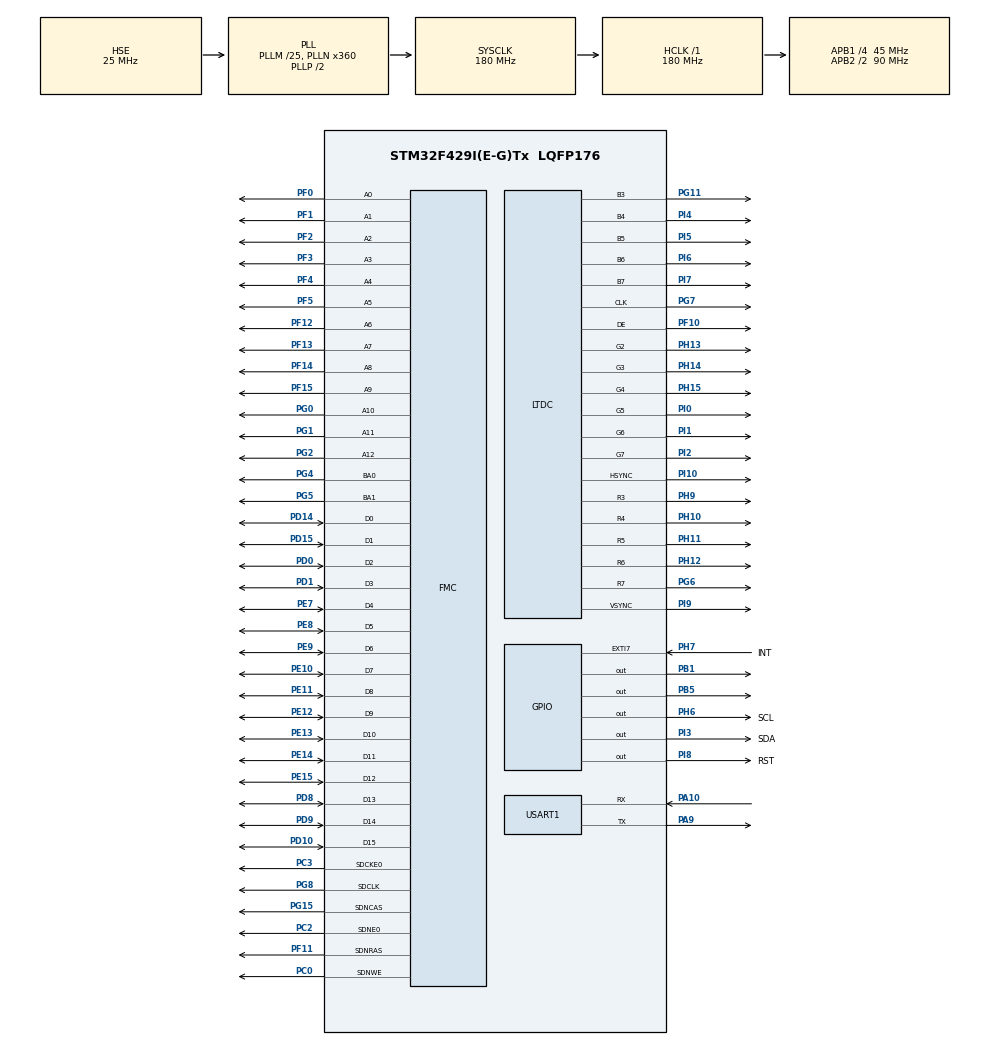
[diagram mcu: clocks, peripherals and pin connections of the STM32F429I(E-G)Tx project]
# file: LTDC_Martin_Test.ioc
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DMA2D.ColorMode=DMA2D_OUTPUT_RGB565
DMA2D.Mode=DMA2D_R2M
FMC.CASLatency1=FMC_SDRAM_CAS_LATENCY_3
FMC.ColumnBitsNumber1=FMC_SDRAM_COLUMN_BITS_NUM_9
FMC.ExitSelfRefreshDelay1=8
FMC.LoadToActiveDelay1=2
FMC.RCDDelay1=2
FMC.RPDelay1=2
FMC.ReadPipeDelay1=FMC_SDRAM_RPIPE_DELAY_1
FMC.RowCycleDelay1=6
FMC.SDClockPeriod1=FMC_SDRAM_CLOCK_PERIOD_2
FMC.SelfRefreshTime1=6
FMC.WriteRecoveryTime1=4
FREERTOS.Tasks01=LEDTask,24,128,StartDefaultTask,Default,NULL,Dynamic,NULL,NULL;LCDTask,8,128,StartTask02,Default,NULL,Dynamic,NULL,NULL
LTDC.ActiveW=800
LTDC.Alpha_L0=255
LTDC.FBStartAdress_L0=0xC0000000
LTDC.FBStartAdress_L1=0xC0200000
LTDC.HBP=88
LTDC.HFP=40
LTDC.HSync=48
LTDC.ImageHeight_L0=600
LTDC.ImageHeight_L1=600
LTDC.ImageWidth_L0=1024
LTDC.ImageWidth_L1=1024
LTDC.PixelFormat_L0=LTDC_PIXEL_FORMAT_RGB565
LTDC.PixelFormat_L1=LTDC_PIXEL_FORMAT_RGB565
LTDC.VBP=32
LTDC.VFP=13
LTDC.VSPolarity=LTDC_VSPOLARITY_AL
LTDC.VSync=3
LTDC.WindowX1_L0=1024
LTDC.WindowX1_L1=1024
LTDC.WindowY1_L0=600
LTDC.WindowY1_L1=600
Mcu.Family=STM32F4
Mcu.Name=STM32F429I(E-G)Tx
Mcu.Package=LQFP176
NVIC.DMA2D_IRQn=true\:5\:0\:false\:false\:true\:true\:true\:true\:true
NVIC.EXTI9_5_IRQn=true\:1\:1\:true\:false\:true\:true\:true\:true\:true
NVIC.PriorityGroup=NVIC_PRIORITYGROUP_4
NVIC.USART1_IRQn=true\:1\:1\:true\:false\:true\:true\:true\:true\:true
PA10.Mode=Asynchronous
PA10.Signal=USART1_RX
PA9.Mode=Asynchronous
PA9.Signal=USART1_TX
PB1.Signal=GPIO_Output
PB5.GPIO_PuPd=GPIO_PULLUP
PB5.GPIO_Speed=GPIO_SPEED_FREQ_VERY_HIGH
PB5.PinState=GPIO_PIN_SET
PB5.Signal=GPIO_Output
PC0.GPIO_PuPd=GPIO_PULLUP
PC0.Signal=FMC_SDNWE
PC2.GPIO_PuPd=GPIO_PULLUP
PC2.Mode=SdramChipSelect1_1
PC2.Signal=FMC_SDNE0
PC3.GPIO_PuPd=GPIO_PULLUP
PC3.Mode=SdramChipSelect1_1
PC3.Signal=FMC_SDCKE0
PD0.GPIO_PuPd=GPIO_PULLUP
PD0.Signal=FMC_D2_DA2
PD1.GPIO_PuPd=GPIO_PULLUP
PD1.Signal=FMC_D3_DA3
PD10.GPIO_PuPd=GPIO_PULLUP
PD10.Signal=FMC_D15_DA15
PD14.GPIO_PuPd=GPIO_PULLUP
PD14.Signal=FMC_D0_DA0
PD15.GPIO_PuPd=GPIO_PULLUP
PD15.Signal=FMC_D1_DA1
PD8.GPIO_PuPd=GPIO_PULLUP
PD8.Signal=FMC_D13_DA13
PD9.GPIO_PuPd=GPIO_PULLUP
PD9.Signal=FMC_D14_DA14
PE0.Signal=FMC_NBL0
PE1.Signal=FMC_NBL1
PE10.GPIO_PuPd=GPIO_PULLUP
PE10.Signal=FMC_D7_DA7
PE11.GPIO_PuPd=GPIO_PULLUP
PE11.Signal=FMC_D8_DA8
PE12.GPIO_PuPd=GPIO_PULLUP
PE12.Signal=FMC_D9_DA9
PE13.GPIO_PuPd=GPIO_PULLUP
PE13.Signal=FMC_D10_DA10
PE14.GPIO_PuPd=GPIO_PULLUP
PE14.Signal=FMC_D11_DA11
PE15.GPIO_PuPd=GPIO_PULLUP
PE15.Signal=FMC_D12_DA12
PE7.GPIO_PuPd=GPIO_PULLUP
PE7.Signal=FMC_D4_DA4
PE8.GPIO_PuPd=GPIO_PULLUP
PE8.Signal=FMC_D5_DA5
PE9.GPIO_PuPd=GPIO_PULLUP
PE9.Signal=FMC_D6_DA6
PF0.GPIO_PuPd=GPIO_PULLUP
PF0.Signal=FMC_A0
PF1.GPIO_PuPd=GPIO_PULLUP
PF1.Signal=FMC_A1
PF10.GPIO_Speed=GPIO_SPEED_FREQ_VERY_HIGH
PF10.Mode=RGB565
PF10.Signal=LTDC_DE
PF11.GPIO_PuPd=GPIO_PULLUP
PF11.Signal=FMC_SDNRAS
PF12.GPIO_PuPd=GPIO_PULLUP
PF12.Signal=FMC_A6
PF13.GPIO_PuPd=GPIO_PULLUP
PF13.Signal=FMC_A7
PF14.GPIO_PuPd=GPIO_PULLUP
PF14.Signal=FMC_A8
PF15.GPIO_PuPd=GPIO_PULLUP
PF15.Signal=FMC_A9
PF2.GPIO_PuPd=GPIO_PULLUP
PF2.Signal=FMC_A2
PF3.GPIO_PuPd=GPIO_PULLUP
PF3.Signal=FMC_A3
PF4.GPIO_PuPd=GPIO_PULLUP
PF4.Signal=FMC_A4
PF5.GPIO_PuPd=GPIO_PULLUP
PF5.Signal=FMC_A5
PG0.GPIO_PuPd=GPIO_PULLUP
PG0.Signal=FMC_A10
PG1.GPIO_PuPd=GPIO_PULLUP
PG1.Signal=FMC_A11
PG11.GPIO_Speed=GPIO_SPEED_FREQ_VERY_HIGH
PG11.Mode=RGB565
PG11.Signal=LTDC_B3
PG15.GPIO_PuPd=GPIO_PULLUP
PG15.Signal=FMC_SDNCAS
PG2.GPIO_PuPd=GPIO_PULLUP
PG2.Signal=FMC_A12
PG4.GPIO_PuPd=GPIO_PULLUP
PG4.Signal=FMC_A14_BA0
PG5.GPIO_PuPd=GPIO_PULLUP
PG5.Signal=FMC_A15_BA1
PG6.GPIO_Speed=GPIO_SPEED_FREQ_VERY_HIGH
PG6.Mode=RGB565
PG6.Signal=LTDC_R7
PG7.GPIO_Speed=GPIO_SPEED_FREQ_VERY_HIGH
PG7.Mode=RGB565
PG7.Signal=LTDC_CLK
PG8.GPIO_PuPd=GPIO_PULLUP
PG8.Signal=FMC_SDCLK
PH0/OSC_IN.Mode=HSE-External-Oscillator
PH0/OSC_IN.Signal=RCC_OSC_IN
PH1/OSC_OUT.Mode=HSE-External-Oscillator
PH1/OSC_OUT.Signal=RCC_OSC_OUT
PH10.GPIO_Speed=GPIO_SPEED_FREQ_VERY_HIGH
PH10.Mode=RGB565
PH10.Signal=LTDC_R4
PH11.GPIO_Speed=GPIO_SPEED_FREQ_VERY_HIGH
PH11.Mode=RGB565
PH11.Signal=LTDC_R5
PH12.GPIO_Speed=GPIO_SPEED_FREQ_VERY_HIGH
PH12.Mode=RGB565
PH12.Signal=LTDC_R6
PH13.GPIO_Speed=GPIO_SPEED_FREQ_VERY_HIGH
PH13.Mode=RGB565
PH13.Signal=LTDC_G2
PH14.GPIO_Speed=GPIO_SPEED_FREQ_VERY_HIGH
PH14.Mode=RGB565
PH14.Signal=LTDC_G3
PH15.GPIO_Speed=GPIO_SPEED_FREQ_VERY_HIGH
PH15.Mode=RGB565
PH15.Signal=LTDC_G4
PH6.GPIO_Label=SCL
PH6.GPIO_Speed=GPIO_SPEED_FREQ_VERY_HIGH
PH6.Signal=GPIO_Output
PH7.GPIO_Label=INT
PH7.GPIO_ModeDefaultEXTI=GPIO_MODE_IT_FALLING
PH7.GPIO_PuPd=GPIO_PULLUP
PH7.Signal=GPXTI7
PH9.GPIO_Speed=GPIO_SPEED_FREQ_VERY_HIGH
PH9.Mode=RGB565
PH9.Signal=LTDC_R3
PI0.GPIO_Speed=GPIO_SPEED_FREQ_VERY_HIGH
PI0.Mode=RGB565
PI0.Signal=LTDC_G5
PI1.GPIO_Speed=GPIO_SPEED_FREQ_VERY_HIGH
PI1.Mode=RGB565
PI1.Signal=LTDC_G6
PI10.GPIO_Speed=GPIO_SPEED_FREQ_VERY_HIGH
PI10.Mode=RGB565
PI10.Signal=LTDC_HSYNC
PI2.GPIO_Speed=GPIO_SPEED_FREQ_VERY_HIGH
PI2.Mode=RGB565
PI2.Signal=LTDC_G7
PI3.GPIO_Label=SDA
PI3.GPIO_Speed=GPIO_SPEED_FREQ_VERY_HIGH
PI3.Signal=GPIO_Output
PI4.GPIO_Speed=GPIO_SPEED_FREQ_VERY_HIGH
PI4.Mode=RGB565
PI4.Signal=LTDC_B4
PI5.GPIO_Speed=GPIO_SPEED_FREQ_VERY_HIGH
PI5.Mode=RGB565
PI5.Signal=LTDC_B5
PI6.GPIO_Speed=GPIO_SPEED_FREQ_VERY_HIGH
PI6.Mode=RGB565
PI6.Signal=LTDC_B6
PI7.GPIO_Speed=GPIO_SPEED_FREQ_VERY_HIGH
PI7.Mode=RGB565
PI7.Signal=LTDC_B7
PI8.GPIO_Label=RST
PI8.Signal=GPIO_Output
PI9.GPIO_Speed=GPIO_SPEED_FREQ_VERY_HIGH
PI9.Mode=RGB565
PI9.Signal=LTDC_VSYNC
ProjectManager.HeapSize=0x1000
ProjectManager.StackSize=0x1000
ProjectManager.TargetToolchain=STM32CubeIDE
RCC.48MHZClocksFreq_Value=45000000
RCC.AHBFreq_Value=180000000
RCC.APB1CLKDivider=RCC_HCLK_DIV4
RCC.APB1Freq_Value=45000000
RCC.APB1TimFreq_Value=90000000
RCC.APB2CLKDivider=RCC_HCLK_DIV2
RCC.APB2Freq_Value=90000000
RCC.APB2TimFreq_Value=180000000
RCC.CortexFreq_Value=180000000
RCC.HCLKFreq_Value=180000000
RCC.HSE_VALUE=25000000
RCC.HSI_VALUE=16000000
RCC.LSE_VALUE=32768
RCC.PLLM=25
RCC.PLLN=360
RCC.PLLQ=8
RCC.PLLSAIN=152
RCC.PLLSourceVirtual=RCC_PLLSOURCE_HSE
RCC.SYSCLKFreq_VALUE=180000000
RCC.SYSCLKSource=RCC_SYSCLKSOURCE_PLLCLK
RCC.VCOOutputFreq_Value=360000000
SH.FMC_A0.0=FMC_A0,13b-sda1
SH.FMC_A1.0=FMC_A1,13b-sda1
SH.FMC_A10.0=FMC_A10,13b-sda1
SH.FMC_A11.0=FMC_A11,13b-sda1
SH.FMC_A12.0=FMC_A12,13b-sda1
SH.FMC_A14_BA0.0=FMC_BA0,FourSdramBanks1
SH.FMC_A15_BA1.0=FMC_BA1,FourSdramBanks1
SH.FMC_A2.0=FMC_A2,13b-sda1
SH.FMC_A3.0=FMC_A3,13b-sda1
SH.FMC_A4.0=FMC_A4,13b-sda1
SH.FMC_A5.0=FMC_A5,13b-sda1
SH.FMC_A6.0=FMC_A6,13b-sda1
SH.FMC_A7.0=FMC_A7,13b-sda1
SH.FMC_A8.0=FMC_A8,13b-sda1
SH.FMC_A9.0=FMC_A9,13b-sda1
SH.FMC_D0_DA0.0=FMC_D0,sd-16b-d1
SH.FMC_D10_DA10.0=FMC_D10,sd-16b-d1
SH.FMC_D11_DA11.0=FMC_D11,sd-16b-d1
SH.FMC_D12_DA12.0=FMC_D12,sd-16b-d1
SH.FMC_D13_DA13.0=FMC_D13,sd-16b-d1
SH.FMC_D14_DA14.0=FMC_D14,sd-16b-d1
SH.FMC_D15_DA15.0=FMC_D15,sd-16b-d1
SH.FMC_D1_DA1.0=FMC_D1,sd-16b-d1
SH.FMC_D2_DA2.0=FMC_D2,sd-16b-d1
SH.FMC_D3_DA3.0=FMC_D3,sd-16b-d1
SH.FMC_D4_DA4.0=FMC_D4,sd-16b-d1
SH.FMC_D5_DA5.0=FMC_D5,sd-16b-d1
SH.FMC_D6_DA6.0=FMC_D6,sd-16b-d1
SH.FMC_D7_DA7.0=FMC_D7,sd-16b-d1
SH.FMC_D8_DA8.0=FMC_D8,sd-16b-d1
SH.FMC_D9_DA9.0=FMC_D9,sd-16b-d1
SH.FMC_NBL0.0=FMC_NBL0
SH.FMC_NBL1.0=FMC_NBL1
SH.FMC_SDCLK.0=FMC_SDCLK,13b-sda1
SH.FMC_SDNCAS.0=FMC_SDNCAS,13b-sda1
SH.FMC_SDNRAS.0=FMC_SDNRAS,13b-sda1
SH.FMC_SDNWE.0=FMC_SDNWE,13b-sda1
USART1.VirtualMode=VM_ASYNC
VP_CRC_VS_CRC.Mode=CRC_Activate
VP_DMA2D_VS_DMA2D.Mode=DMA2D_Activate
VP_FREERTOS_VS_CMSIS_V2.Mode=CMSIS_V2
board=custom

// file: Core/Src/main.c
/* USER CODE BEGIN Header */
/**
 ******************************************************************************
 * @file           : main.c
 * @brief          : Main program body
 ******************************************************************************
 * @attention
 *
 * <h2><center>&copy; Copyright (c) 2023 STMicroelectronics.
 * All rights reserved.</center></h2>
 *
 * This software component is licensed by ST under Ultimate Liberty license
 * SLA0044, the "License"; You may not use this file except in compliance with
 * the License. You may obtain a copy of the License at:
 *                             www.st.com/SLA0044
 *
 ******************************************************************************
 */
/* USER CODE END Header */
#include "main.h"

#include "dma2d.h"
#include "fmc.h"
#include "gpio.h"
#include "ltdc.h"
#include "usart.h"

#include "cmsis_os.h"

/* USER CODE BEGIN Includes */
#include "LCD_LTDC.h"
#include "fonts.h"
#include "sdram.h"
//#include "FT5426.h"
/* USER CODE END Includes */

void SystemClock_Config(void);
void MX_FREERTOS_Init(void);

int main(void) {

	/* MCU Configuration--------------------------------------------------------*/

	/* Reset of all peripherals, Initializes the Flash interface and the Systick. */
	HAL_Init();

	/* Configure the system clock */
	SystemClock_Config();

	/* Initialize all configured peripherals */
	MX_GPIO_Init();
	MX_LTDC_Init();
	MX_FMC_Init();
	MX_USART1_UART_Init();
	MX_DMA2D_Init();
	/* USER CODE BEGIN 2 */
	BSP_LCD_Init();
	HAL_GPIO_WritePin(GPIOB, GPIO_PIN_5, GPIO_PIN_SET);
	__HAL_RCC_DMA2D_CLK_ENABLE();
	/* USER CODE END 2 */

	/* Init scheduler */
	osKernelInitialize(); /* Call init function for freertos objects (in freertos.c) */
	MX_FREERTOS_Init();

	/* Start scheduler */
	osKernelStart();

	/* We should never get here as control is now taken by the scheduler */
	/* Infinite loop */
	/* USER CODE BEGIN WHILE */
	BSP_LCD_Clear(LCD_COLOR_WHITE);

	volatile uint32_t last_ticks = 0;
	uint8_t LED = 0;
	while (1) {
		if (HAL_GetTick() - last_ticks >= 50) {
			if (LED) {
				HAL_GPIO_WritePin(GPIOB, GPIO_PIN_1, SET);
			} else {
				HAL_GPIO_WritePin(GPIOB, GPIO_PIN_1, RESET);
			}
			LED = (++LED) % 2;
			last_ticks = HAL_GetTick();
		}

		/* USER CODE END WHILE */

	}
}

void SystemClock_Config(void) {
	RCC_OscInitTypeDef RCC_OscInitStruct = {0};
	RCC_ClkInitTypeDef RCC_ClkInitStruct = {0};

	/** Configure the main internal regulator output voltage
	 */
	__HAL_RCC_PWR_CLK_ENABLE();
	__HAL_PWR_VOLTAGESCALING_CONFIG(PWR_REGULATOR_VOLTAGE_SCALE1);

	/** Initializes the RCC Oscillators according to the specified parameters
	 * in the RCC_OscInitTypeDef structure.
	 */
	RCC_OscInitStruct.OscillatorType = RCC_OSCILLATORTYPE_HSE;
	RCC_OscInitStruct.HSEState = RCC_HSE_ON;
	RCC_OscInitStruct.PLL.PLLState = RCC_PLL_ON;
	RCC_OscInitStruct.PLL.PLLSource = RCC_PLLSOURCE_HSE;
	RCC_OscInitStruct.PLL.PLLM = 25;
	RCC_OscInitStruct.PLL.PLLN = 360;
	RCC_OscInitStruct.PLL.PLLP = RCC_PLLP_DIV2;
	RCC_OscInitStruct.PLL.PLLQ = 8;
	if (HAL_RCC_OscConfig(&RCC_OscInitStruct) != HAL_OK) {
		Error_Handler();
	}

	/** Activate the Over-Drive mode
	 */
	if (HAL_PWREx_EnableOverDrive() != HAL_OK) {
		Error_Handler();
	}

	/** Initializes the CPU, AHB and APB buses clocks
	 */
	RCC_ClkInitStruct.ClockType = RCC_CLOCKTYPE_HCLK | RCC_CLOCKTYPE_SYSCLK | RCC_CLOCKTYPE_PCLK1 | RCC_CLOCKTYPE_PCLK2;
	RCC_ClkInitStruct.SYSCLKSource = RCC_SYSCLKSOURCE_PLLCLK;
	RCC_ClkInitStruct.AHBCLKDivider = RCC_SYSCLK_DIV1;
	RCC_ClkInitStruct.APB1CLKDivider = RCC_HCLK_DIV4;
	RCC_ClkInitStruct.APB2CLKDivider = RCC_HCLK_DIV2;

	if (HAL_RCC_ClockConfig(&RCC_ClkInitStruct, FLASH_LATENCY_5) != HAL_OK) {
		Error_Handler();
	}
}

void Error_Handler(void) {
}

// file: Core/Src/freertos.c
/* USER CODE BEGIN Header */
/**
 ******************************************************************************
 * File Name          : freertos.c
 * Description        : Code for freertos applications
 ******************************************************************************
 * @attention
 *
 * Copyright (c) 2023 STMicroelectronics.
 * All rights reserved.
 *
 * This software is licensed under terms that can be found in the LICENSE file
 * in the root directory of this software component.
 * If no LICENSE file comes with this software, it is provided AS-IS.
 *
 ******************************************************************************
 */
/* USER CODE END Header */

#include "FreeRTOS.h"
#include "task.h"
#include "main.h"
#include "cmsis_os.h"

/* USER CODE BEGIN Variables */
// osThreadId_t LEDTaskHandle;
// const osThreadAttr_t LEDTask_attributes = {
// 	.name = "LEDTask",
// 	.stack_size = 128 * 4,
// 	.priority = (osPriority_t)osPriorityNormal,
// };
DEFINE_THREAD_ATTR(led_thread, osPriorityNormal);

/* USER CODE END Variables */
/* Definitions for LEDTask */
osThreadId_t LEDTaskHandle;
const osThreadAttr_t LEDTask_attributes = {
  .name = "LEDTask",
  .stack_size = 128 * 4,
  .priority = (osPriority_t) osPriorityNormal,
};
/* Definitions for LCDTask */
osThreadId_t LCDTaskHandle;
const osThreadAttr_t LCDTask_attributes = {
  .name = "LCDTask",
  .stack_size = 128 * 4,
  .priority = (osPriority_t) osPriorityLow,
};

/* USER CODE BEGIN FunctionPrototypes */
void led_task(void* argument);

/* USER CODE END FunctionPrototypes */

void StartDefaultTask(void *argument);
void StartTask02(void *argument);

void MX_FREERTOS_Init(void); /* (MISRA C 2004 rule 8.1) */

void MX_FREERTOS_Init(void) {

  /* Create the thread(s) */
  /* creation of LEDTask */
  LEDTaskHandle = osThreadNew(StartDefaultTask, NULL, &LEDTask_attributes);

  /* creation of LCDTask */
  LCDTaskHandle = osThreadNew(StartTask02, NULL, &LCDTask_attributes);

  /* USER CODE BEGIN RTOS_THREADS */
	/* add threads, ... */
	// osThreadId_t LEDTaskHandle = osThreadNew(led_task, NULL, &LEDTask_attr);

  /* USER CODE END RTOS_THREADS */

}

void StartDefaultTask(void *argument)
{
  for(;;)
  {
    osDelay(1);
  }
}

void StartTask02(void *argument)
{
  for(;;)
  {
    osDelay(1);
  }
}
